# f2838x_hwbist_regs register map
Vendor: Texas Instruments
Peripheral module from a debugger description file (folder C2000).
Address unit: 16 bits
Registers are 32-bit, read-only, no defined reset value unless marked. A register's access mark holds for its fields unless they carry their own. Offsets are as the file gives them; lines under a group give offsets from that group; [hi:lo] are bit positions; {n}, {i} and the like mark numbered series; 'fields as' and 'values as' point back to an identical list; <NAME> marks a mode.

## HWBIST_REGS — HWBIST Registers
0x04 CSTCGCR1 rw — STC Global Control Register1
  [31:0] MICROCFG — Micro Configuration
0x0C CSTCGCR3 rw — STC Global Control Register3
  [3:0] ILS — Interrupt Logging Start
0x10 CSTCGCR4 rw — STC Global Control Register4
  [3:0] BISTGO — BIST Start
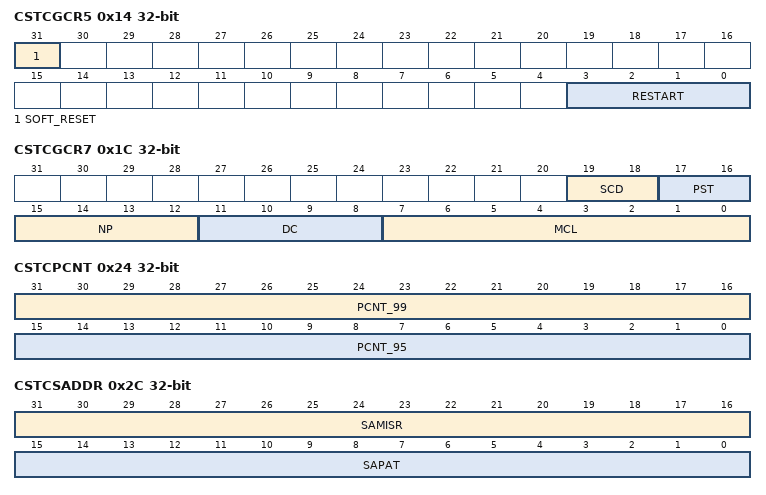
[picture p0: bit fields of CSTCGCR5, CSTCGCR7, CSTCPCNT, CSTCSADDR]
0x14 CSTCGCR5 rw — STC Global Control Register5
  [31] SOFT_RESET — Soft reset to BIST controller
  [3:0] RESTART — Restart Enable
0x18 CSTCGCR6 rw — STC Global Control Register6
  [1:0] COV — COVERAGE
0x1C CSTCGCR7 rw — STC Global Control Register7
  [19:18] SCD — SHIFT_CLOCK_DIVISION
  [17:16] PST — PATTERN SET TYPE
  [15:12] NP — NUM OF PIPELINE STAGES
  [11:8] DC — DEAD CYCLES
  [7:0] MCL — MAX CHAIN LENGTH
0x20 CSTCGCR8 rw — STC Global Control Register8
  [15:0] CPC — COMPARE PATTERN CNT
0x24 CSTCPCNT rw — STC Pattern Count Register
  [31:16] PCNT_99 — PATTERNS FOR 99% COVERAGE
  [15:0] PCNT_95 — PATTERNS FOR 95% COVERAGE
0x28 CSTCCONFIG rw — STC Registers Configuration Status
  [3:0] CFGDONE — Configuration done
0x2C CSTCSADDR rw — STC ROM Start Address
  [31:16] SAMISR — MISR ROM Start Address
  [15:0] SAPAT — PATTERN ROM Start Address
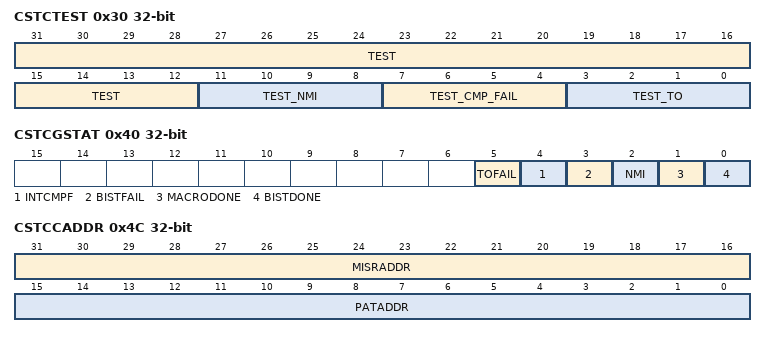
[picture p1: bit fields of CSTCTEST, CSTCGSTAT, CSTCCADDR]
0x30 CSTCTEST rw — C28 HW BIST Test Register
  [31:12] TEST — TEST Bits
  [11:8] TEST_NMI
  [7:4] TEST_CMP_FAIL — Test MISR compare fail
  [3:0] TEST_TO — Test_ Time_Out
0x34 CSTCRET rw — C28 Return PC Address
  [31:0] RETADDR — Return Address
0x38 CSTCCRD rw — C28 Context Restore Done Register
  [3:0] Restore_Done — Context Restone Done
0x40 CSTCGSTAT — STC Global Status Register
  [5] TOFAIL — Time Out Failure
  [4] INTCMPF — Intermediate Comparison Failure
  [3] BISTFAIL — HW BIST Failure
  [2] NMI — Exit due to NMI
  [1] MACRODONE — Macro test slot Complete
  [0] BISTDONE — HW BIST Complete
0x48 CSTCCPCR — STC Current Pattern Count Register
  [15:0] PATCNT — Current Pattern Count
0x4C CSTCCADDR — STC Current ROM Address Register
  [31:16] MISRADDR — Current MISR ROM Address
  [15:0] PATADDR — Current Pattern ROM Address
{0x50+4i} CSTCMISR{i} (i=0..15) — MISR Result Register {i}
  [31:0] MISR{i} — Final MISR Result[{32i+31}:{32i}]
0xA0 CSTCSEM rw — STC Semaphore register
  [1:0] SEMAPHORE
